VERSION ""

NS_ :

BS_:

BU_: RADAR GWM BCM
VAL_TABLE_ VAL_Gear_signal 3 "Driving" 2 "Neutral" 1 "Reverse" 0 "Parking" ;
VAL_TABLE_ VAL_MO_sig_ReadytoDrive 2 "Drive_active" 1 "No_Drive_Active" 0 "No Drive_inactive" ;
VAL_TABLE_ VAL_ACC_Set_signal 1 "Activated" 0 "Not activated" ;
VAL_TABLE_ VAL_ACC_MainSwitch_ACC 3 "Error" 2 "Active" 1 "Off" 0 "Init" ;
VAL_TABLE_ VAL_ACC_Int_status 4 "Brake_only_Mode" 3 "Suspend" 2 "Passive" 1 "Active" 0 "Init" ;

BO_ 1245 RDS_Coder_Data_CAN: 2 BCM
 SG_ Sig_Spdmtr_Rq : 0|16@1+ (1,0) [0|240] "" Vector__XXX

BO_ 1792 Gear_Message: 1 GWM
 SG_ Gear_signal : 0|2@1+ (1,0) [0|3] "" Vector__XXX

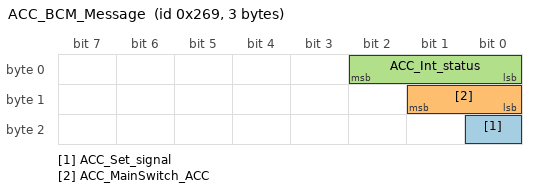
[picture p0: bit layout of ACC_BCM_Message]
BO_ 617 ACC_BCM_Message: 3 BCM
 SG_ ACC_Set_signal : 16|1@1+ (1,0) [0|1] "" Vector__XXX
 SG_ ACC_MainSwitch_ACC : 8|2@1+ (1,0) [0|3] "" Vector__XXX
 SG_ ACC_Int_status : 0|3@1+ (1,0) [0|0] "" Vector__XXX

BO_ 389 MO_Message_1: 1 GWM
 SG_ MO_sig_ReadytoDrive : 0|2@1+ (1,0) [0|3] "" Vector__XXX

BA_DEF_ BU_  "NodeLayerModule" STRING ;
BA_DEF_ BU_  "ILUsed" ENUM  "YES","NO","vector_leerstring";
BA_DEF_ BO_  "GenMsgSendType" ENUM  "FixedPeriodic","EventPeriodic","Event";
BA_DEF_ BO_  "GenMsgCycleTime" INT 0 20000;
BA_DEF_DEF_  "NodeLayerModule" "CANoeILNLVector.dll";
BA_DEF_DEF_  "ILUsed" "YES";
BA_DEF_DEF_  "GenMsgSendType" "FixedPeriodic";
BA_DEF_DEF_  "GenMsgCycleTime" 50;
VAL_ 1792 Gear_signal 3 "Driving" 2 "Neutral" 1 "Reverse" 0 "Parking" ;
VAL_ 617 ACC_Set_signal 1 "Activated" 0 "Not activated" ;
VAL_ 617 ACC_MainSwitch_ACC 3 "Error" 2 "Active" 1 "Off" 0 "Init" ;
VAL_ 617 ACC_Int_status 4 "Brake_only_Mode" 3 "Suspend" 2 "Passive" 1 "Active" 0 "Init" ;
VAL_ 389 MO_sig_ReadytoDrive 2 "Drive_active" 1 "No_Drive_Active" 0 "No Drive_inactive" ;
